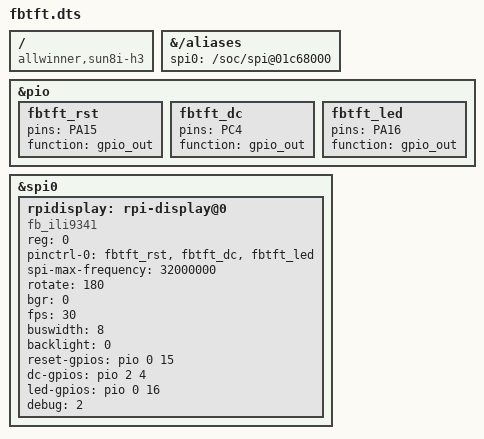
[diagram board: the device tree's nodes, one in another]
/dts-v1/;
/plugin/;

/ {
	compatible = "allwinner,sun8i-h3";

	fragment@0 {
                target-path = "/aliases";
                __overlay__ {
                        spi0 = "/soc/spi@01c68000";
                };
        };

	fragment@1 {
		target = <&pio>;
		__overlay__ {
                        fbtft_rst: fbtft_rst {
                                pins = "PA15";
                                function = "gpio_out";
                        };
                        fbtft_dc: fbtft_dc {
                                pins = "PC4";
                                function = "gpio_out";
                        };
                        fbtft_led: fbtft_led {
                                pins = "PA16";
                                function = "gpio_out";
                        };

		};
	};

	fragment@2 {
		target = <&spi0>;
		__overlay__ {
			/* needed to avoid dtc warning */
			#address-cells = <1>;
			#size-cells = <0>;

			rpidisplay: rpi-display@0 {
				compatible = "fb_ili9341";
				reg = <0>;

				pinctrl-names = "default";
				pinctrl-0 = <&fbtft_rst &fbtft_dc &fbtft_led>;

				spi-max-frequency = <32000000>;
				rotate = <180>;
				bgr = <0>;
				fps = <30>;
				buswidth = <8>;
				backlight = <0>;
				reset-gpios = <&pio 0 15 0>;	/* PA15, pio out */
				dc-gpios = <&pio 2 4 0>;	/* PC4, pio out */
				led-gpios = <&pio 0 16 0>;	/* PA16, pio out */
				debug = <2>;
			};
		};
	};
};
